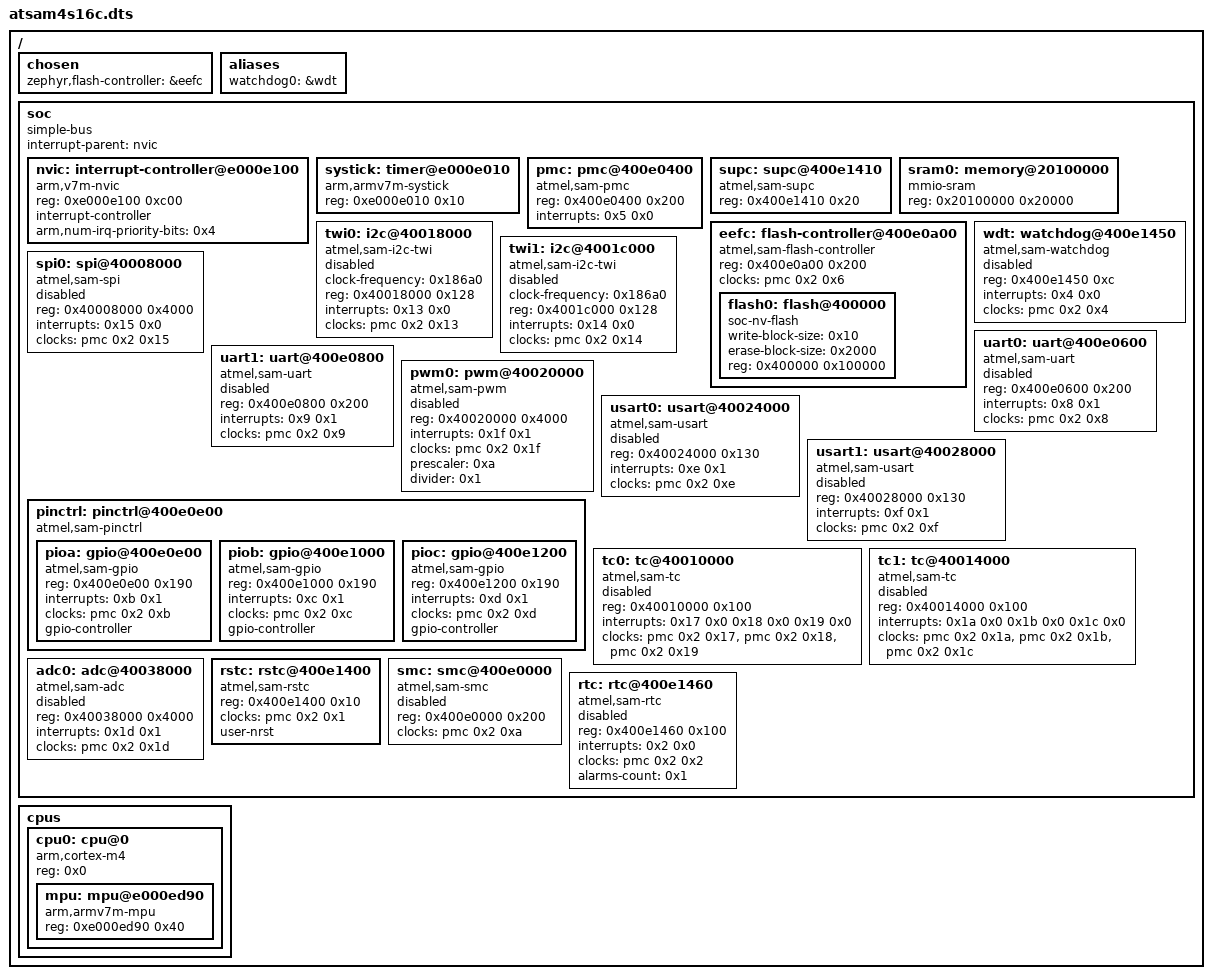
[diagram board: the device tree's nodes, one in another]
/dts-v1/;

/ {
	#address-cells = < 0x1 >;
	#size-cells = < 0x1 >;
	chosen {
		zephyr,flash-controller = &eefc;
	};
	aliases {
		watchdog0 = &wdt;
	};
	soc {
		#address-cells = < 0x1 >;
		#size-cells = < 0x1 >;
		compatible = "simple-bus";
		interrupt-parent = < &nvic >;
		ranges;
		nvic: interrupt-controller@e000e100 {
			#address-cells = < 0x1 >;
			compatible = "arm,v7m-nvic";
			reg = < 0xe000e100 0xc00 >;
			interrupt-controller;
			#interrupt-cells = < 0x2 >;
			arm,num-irq-priority-bits = < 0x4 >;
			phandle = < 0x1 >;
		};
		systick: timer@e000e010 {
			compatible = "arm,armv7m-systick";
			reg = < 0xe000e010 0x10 >;
		};
		pmc: pmc@400e0400 {
			compatible = "atmel,sam-pmc";
			reg = < 0x400e0400 0x200 >;
			interrupts = < 0x5 0x0 >;
			#clock-cells = < 0x2 >;
			status = "okay";
			phandle = < 0x2 >;
		};
		supc: supc@400e1410 {
			compatible = "atmel,sam-supc";
			reg = < 0x400e1410 0x20 >;
			#wakeup-source-id-cells = < 0x1 >;
			status = "okay";
		};
		sram0: memory@20100000 {
			compatible = "mmio-sram";
			reg = < 0x20100000 0x20000 >;
		};
		eefc: flash-controller@400e0a00 {
			compatible = "atmel,sam-flash-controller";
			reg = < 0x400e0a00 0x200 >;
			clocks = < &pmc 0x2 0x6 >;
			#address-cells = < 0x1 >;
			#size-cells = < 0x1 >;
			flash0: flash@400000 {
				compatible = "soc-nv-flash";
				write-block-size = < 0x10 >;
				erase-block-size = < 0x2000 >;
				reg = < 0x400000 0x100000 >;
			};
		};
		wdt: watchdog@400e1450 {
			compatible = "atmel,sam-watchdog";
			reg = < 0x400e1450 0xc >;
			interrupts = < 0x4 0x0 >;
			clocks = < &pmc 0x2 0x4 >;
			status = "disabled";
		};
		twi0: i2c@40018000 {
			compatible = "atmel,sam-i2c-twi";
			clock-frequency = < 0x186a0 >;
			reg = < 0x40018000 0x128 >;
			interrupts = < 0x13 0x0 >;
			clocks = < &pmc 0x2 0x13 >;
			status = "disabled";
			#address-cells = < 0x1 >;
			#size-cells = < 0x0 >;
		};
		twi1: i2c@4001c000 {
			compatible = "atmel,sam-i2c-twi";
			clock-frequency = < 0x186a0 >;
			reg = < 0x4001c000 0x128 >;
			interrupts = < 0x14 0x0 >;
			clocks = < &pmc 0x2 0x14 >;
			status = "disabled";
			#address-cells = < 0x1 >;
			#size-cells = < 0x0 >;
		};
		spi0: spi@40008000 {
			compatible = "atmel,sam-spi";
			#address-cells = < 0x1 >;
			#size-cells = < 0x0 >;
			reg = < 0x40008000 0x4000 >;
			interrupts = < 0x15 0x0 >;
			clocks = < &pmc 0x2 0x15 >;
			status = "disabled";
		};
		uart0: uart@400e0600 {
			compatible = "atmel,sam-uart";
			reg = < 0x400e0600 0x200 >;
			interrupts = < 0x8 0x1 >;
			clocks = < &pmc 0x2 0x8 >;
			status = "disabled";
		};
		uart1: uart@400e0800 {
			compatible = "atmel,sam-uart";
			reg = < 0x400e0800 0x200 >;
			interrupts = < 0x9 0x1 >;
			clocks = < &pmc 0x2 0x9 >;
			status = "disabled";
		};
		pwm0: pwm@40020000 {
			compatible = "atmel,sam-pwm";
			reg = < 0x40020000 0x4000 >;
			interrupts = < 0x1f 0x1 >;
			clocks = < &pmc 0x2 0x1f >;
			prescaler = < 0xa >;
			divider = < 0x1 >;
			#pwm-cells = < 0x3 >;
			status = "disabled";
		};
		usart0: usart@40024000 {
			compatible = "atmel,sam-usart";
			reg = < 0x40024000 0x130 >;
			interrupts = < 0xe 0x1 >;
			clocks = < &pmc 0x2 0xe >;
			status = "disabled";
		};
		usart1: usart@40028000 {
			compatible = "atmel,sam-usart";
			reg = < 0x40028000 0x130 >;
			interrupts = < 0xf 0x1 >;
			clocks = < &pmc 0x2 0xf >;
			status = "disabled";
		};
		pinctrl: pinctrl@400e0e00 {
			compatible = "atmel,sam-pinctrl";
			#address-cells = < 0x1 >;
			#size-cells = < 0x1 >;
			ranges = < 0x400e0e00 0x400e0e00 0x600 >;
			status = "okay";
			pioa: gpio@400e0e00 {
				compatible = "atmel,sam-gpio";
				reg = < 0x400e0e00 0x190 >;
				interrupts = < 0xb 0x1 >;
				clocks = < &pmc 0x2 0xb >;
				gpio-controller;
				#gpio-cells = < 0x2 >;
				#atmel,pin-cells = < 0x2 >;
			};
			piob: gpio@400e1000 {
				compatible = "atmel,sam-gpio";
				reg = < 0x400e1000 0x190 >;
				interrupts = < 0xc 0x1 >;
				clocks = < &pmc 0x2 0xc >;
				gpio-controller;
				#gpio-cells = < 0x2 >;
				#atmel,pin-cells = < 0x2 >;
			};
			pioc: gpio@400e1200 {
				compatible = "atmel,sam-gpio";
				reg = < 0x400e1200 0x190 >;
				interrupts = < 0xd 0x1 >;
				clocks = < &pmc 0x2 0xd >;
				gpio-controller;
				#gpio-cells = < 0x2 >;
				#atmel,pin-cells = < 0x2 >;
			};
		};
		tc0: tc@40010000 {
			compatible = "atmel,sam-tc";
			reg = < 0x40010000 0x100 >;
			interrupts = < 0x17 0x0 0x18 0x0 0x19 0x0 >;
			clocks = < &pmc 0x2 0x17 >, < &pmc 0x2 0x18 >, < &pmc 0x2 0x19 >;
			status = "disabled";
		};
		tc1: tc@40014000 {
			compatible = "atmel,sam-tc";
			reg = < 0x40014000 0x100 >;
			interrupts = < 0x1a 0x0 0x1b 0x0 0x1c 0x0 >;
			clocks = < &pmc 0x2 0x1a >, < &pmc 0x2 0x1b >, < &pmc 0x2 0x1c >;
			status = "disabled";
		};
		adc0: adc@40038000 {
			compatible = "atmel,sam-adc";
			reg = < 0x40038000 0x4000 >;
			interrupts = < 0x1d 0x1 >;
			clocks = < &pmc 0x2 0x1d >;
			#address-cells = < 0x1 >;
			#size-cells = < 0x0 >;
			#io-channel-cells = < 0x1 >;
			status = "disabled";
		};
		rstc: rstc@400e1400 {
			compatible = "atmel,sam-rstc";
			reg = < 0x400e1400 0x10 >;
			clocks = < &pmc 0x2 0x1 >;
			user-nrst;
		};
		smc: smc@400e0000 {
			compatible = "atmel,sam-smc";
			#address-cells = < 0x1 >;
			#size-cells = < 0x0 >;
			reg = < 0x400e0000 0x200 >;
			clocks = < &pmc 0x2 0xa >;
			status = "disabled";
		};
		rtc: rtc@400e1460 {
			compatible = "atmel,sam-rtc";
			reg = < 0x400e1460 0x100 >;
			interrupts = < 0x2 0x0 >;
			clocks = < &pmc 0x2 0x2 >;
			alarms-count = < 0x1 >;
			status = "disabled";
		};
	};
	cpus {
		#address-cells = < 0x1 >;
		#size-cells = < 0x0 >;
		cpu0: cpu@0 {
			device_type = "cpu";
			compatible = "arm,cortex-m4";
			reg = < 0x0 >;
			#address-cells = < 0x1 >;
			#size-cells = < 0x1 >;
			mpu: mpu@e000ed90 {
				compatible = "arm,armv7m-mpu";
				reg = < 0xe000ed90 0x40 >;
			};
		};
	};
};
